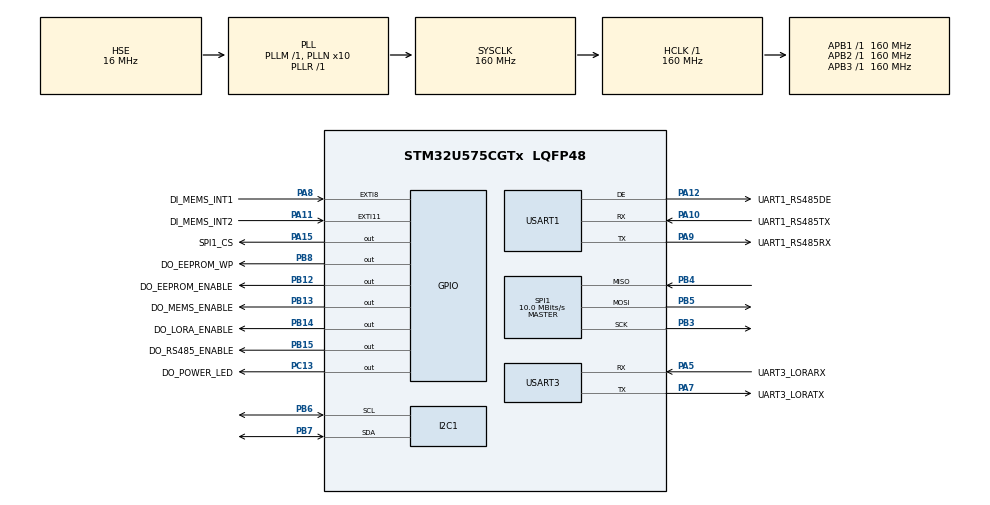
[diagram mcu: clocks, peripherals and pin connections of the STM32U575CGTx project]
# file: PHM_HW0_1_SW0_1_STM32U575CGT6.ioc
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CORTEX_M33_NS.userName=CORTEX_M33
GPDMA1.CIRCULARMODE_GPDMACH0=ENABLE
GPDMA1.CIRCULARMODE_GPDMACH1=DISABLE
GPDMA1.CIRCULARMODE_GPDMACH2=ENABLE
GPDMA1.DESTINC_GPDMACH0=DMA_DINC_INCREMENTED
GPDMA1.DESTINC_GPDMACH1=DMA_DINC_FIXED
GPDMA1.DESTINC_GPDMACH2=DMA_DINC_INCREMENTED
GPDMA1.IPHANDLE_GPDMACH0-SIMPLEREQUEST_GPDMACH0=__NULL
GPDMA1.IPHANDLE_GPDMACH1-SIMPLEREQUEST_GPDMACH1=__NULL
GPDMA1.IPHANDLE_GPDMACH2-SIMPLEREQUEST_GPDMACH2=__NULL
GPDMA1.IPHANDLE_GPDMACH3-SIMPLEREQUEST_GPDMACH3=__NULL
GPDMA1.IPHANDLE_GPDMACH4-SIMPLEREQUEST_GPDMACH4=__NULL
GPDMA1.IPHANDLE_GPDMACH5-SIMPLEREQUEST_GPDMACH5=__NULL
GPDMA1.LINKALLOCATEDPORT_CIRCULAR_GPDMACH1=DMA_LINK_ALLOCATED_PORT1
GPDMA1.REQUEST_GPDMACH0=GPDMA1_REQUEST_USART1_RX
GPDMA1.REQUEST_GPDMACH1=GPDMA1_REQUEST_USART1_TX
GPDMA1.REQUEST_GPDMACH2=GPDMA1_REQUEST_USART3_RX
GPDMA1.REQUEST_GPDMACH3=GPDMA1_REQUEST_USART3_TX
GPDMA1.REQUEST_GPDMACH4=GPDMA1_REQUEST_SPI1_TX
GPDMA1.REQUEST_GPDMACH5=GPDMA1_REQUEST_SPI1_RX
GPDMA1.SRCINC_GPDMACH1=DMA_SINC_INCREMENTED
GPDMA1.SRCINC_GPDMACH3=DMA_SINC_INCREMENTED
I2C1.Timing=0x30909DEC
Mcu.Family=STM32U5
Mcu.Name=STM32U575CGTx
Mcu.Package=LQFP48
NVIC.GPDMA1_Channel0_IRQn=true\:0\:0\:false\:false\:true\:true\:true\:true
NVIC.GPDMA1_Channel1_IRQn=true\:0\:0\:false\:false\:true\:true\:true\:true
NVIC.GPDMA1_Channel2_IRQn=true\:0\:0\:false\:false\:true\:false\:true\:true
NVIC.GPDMA1_Channel3_IRQn=true\:0\:0\:false\:false\:true\:false\:true\:true
NVIC.GPDMA1_Channel4_IRQn=true\:0\:0\:false\:false\:true\:false\:true\:true
NVIC.GPDMA1_Channel5_IRQn=true\:0\:0\:false\:false\:true\:false\:true\:true
NVIC.PriorityGroup=NVIC_PRIORITYGROUP_4
NVIC.SPI1_IRQn=true\:0\:0\:false\:false\:true\:true\:true\:true
NVIC.USART1_IRQn=true\:0\:0\:false\:false\:true\:true\:true\:true
NVIC.USART3_IRQn=true\:0\:0\:false\:false\:true\:true\:true\:true
PA10.GPIO_Label=UART1_RS485TX
PA10.Mode=Asynchronous
PA10.Signal=USART1_RX
PA11.GPIO_Label=DI_MEMS_INT2
PA11.GPIO_ModeDefaultEXTI=GPIO_MODE_IT_RISING
PA11.Signal=GPXTI11
PA12.GPIO_Label=UART1_RS485DE
PA12.Mode=Hardware Flow Control (RS485)
PA12.Signal=USART1_DE
PA13\ (JTMS/SWDIO).Mode=Serial_Wire
PA13\ (JTMS/SWDIO).Signal=DEBUG_JTMS-SWDIO
PA14\ (JTCK/SWCLK).Mode=Serial_Wire
PA14\ (JTCK/SWCLK).Signal=DEBUG_JTCK-SWCLK
PA15\ (JTDI).GPIO_Label=SPI1_CS
PA15\ (JTDI).Signal=GPIO_Output
PA5.GPIO_Label=UART3_LORARX
PA5.Mode=Asynchronous
PA5.Signal=USART3_RX
PA7.GPIO_Label=UART3_LORATX
PA7.Mode=Asynchronous
PA7.Signal=USART3_TX
PA8.GPIO_Label=DI_MEMS_INT1
PA8.GPIO_ModeDefaultEXTI=GPIO_MODE_IT_RISING
PA8.Signal=GPXTI8
PA9.GPIO_Label=UART1_RS485RX
PA9.Mode=Asynchronous
PA9.Signal=USART1_TX
PB12.GPIO_Label=DO_EEPROM_ENABLE
PB12.GPIO_ModeDefaultOutputPP=GPIO_MODE_OUTPUT_OD
PB12.GPIO_PuPd=GPIO_NOPULL
PB12.PinState=GPIO_PIN_SET
PB12.Signal=GPIO_Output
PB13.GPIO_Label=DO_MEMS_ENABLE
PB13.GPIO_ModeDefaultOutputPP=GPIO_MODE_OUTPUT_OD
PB13.GPIO_PuPd=GPIO_NOPULL
PB13.PinState=GPIO_PIN_SET
PB13.Signal=GPIO_Output
PB14.GPIO_Label=DO_LORA_ENABLE
PB14.GPIO_ModeDefaultOutputPP=GPIO_MODE_OUTPUT_OD
PB14.GPIO_PuPd=GPIO_NOPULL
PB14.PinState=GPIO_PIN_SET
PB14.Signal=GPIO_Output
PB15.GPIO_Label=DO_RS485_ENABLE
PB15.GPIO_ModeDefaultOutputPP=GPIO_MODE_OUTPUT_OD
PB15.GPIO_PuPd=GPIO_NOPULL
PB15.PinState=GPIO_PIN_SET
PB15.Signal=GPIO_Output
PB3\ (JTDO/TRACESWO).GPIO_PuPd=GPIO_NOPULL
PB3\ (JTDO/TRACESWO).GPIO_Speed=GPIO_SPEED_FREQ_HIGH
PB3\ (JTDO/TRACESWO).Mode=Full_Duplex_Master
PB3\ (JTDO/TRACESWO).Signal=SPI1_SCK
PB4\ (NJTRST).GPIO_PuPd=GPIO_NOPULL
PB4\ (NJTRST).GPIO_Speed=GPIO_SPEED_FREQ_HIGH
PB4\ (NJTRST).Mode=Full_Duplex_Master
PB4\ (NJTRST).Signal=SPI1_MISO
PB5.GPIO_PuPd=GPIO_NOPULL
PB5.GPIO_Speed=GPIO_SPEED_FREQ_HIGH
PB5.Mode=Full_Duplex_Master
PB5.Signal=SPI1_MOSI
PB6.Mode=I2C
PB6.Signal=I2C1_SCL
PB7.Mode=I2C
PB7.Signal=I2C1_SDA
PB8.GPIO_Label=DO_EEPROM_WP
PB8.Signal=GPIO_Output
PC13.GPIO_Label=DO_POWER_LED
PC13.GPIO_ModeDefaultOutputPP=GPIO_MODE_OUTPUT_OD
PC13.GPIO_PuPd=GPIO_NOPULL
PC13.PinState=GPIO_PIN_SET
PC13.Signal=GPIO_Output
PH0-OSC_IN\ (PH0).Mode=HSE-External-Oscillator
PH0-OSC_IN\ (PH0).Signal=RCC_OSC_IN
PH1-OSC_OUT\ (PH1).Mode=HSE-External-Oscillator
PH1-OSC_OUT\ (PH1).Signal=RCC_OSC_OUT
ProjectManager.HeapSize=0x200
ProjectManager.StackSize=0x400
ProjectManager.TargetToolchain=STM32CubeIDE
RCC.ADCFreq_Value=16000000
RCC.AHBFreq_Value=160000000
RCC.APB1Freq_Value=160000000
RCC.APB1TimFreq_Value=160000000
RCC.APB2Freq_Value=160000000
RCC.APB2TimFreq_Value=160000000
RCC.APB3Freq_Value=160000000
RCC.CortexFreq_Value=160000000
RCC.EPOD_VALUE=16000000
RCC.HCLKFreq_Value=160000000
RCC.HSE_VALUE=16000000
RCC.HSI48_VALUE=48000000
RCC.HSI_VALUE=16000000
RCC.LSE_VALUE=32768
RCC.LSIDIV_VALUE=32000
RCC.MSI_VALUE=4000000
RCC.PLL1R=1
RCC.PLLFRACN=0
RCC.PLLN=10
RCC.PLLSourceVirtual=RCC_PLLSOURCE_HSE
RCC.SYSCLKFreq_VALUE=160000000
RCC.SYSCLKSource=RCC_SYSCLKSOURCE_PLLCLK
RCC.USBFreq_Value=48000000
RCC.VCOOutputFreq_Value=160000000
SPI1.BaudRatePrescaler=SPI_BAUDRATEPRESCALER_16
SPI1.CalculateBaudRate=10.0 MBits/s
SPI1.DataSize=SPI_DATASIZE_8BIT
SPI1.Direction=SPI_DIRECTION_2LINES
SPI1.IOSwap=SPI_IO_SWAP_ENABLE
SPI1.Mode=SPI_MODE_MASTER
SPI1.VirtualType=VM_MASTER
USART1.VirtualMode-Asynchronous=VM_ASYNC
USART1.VirtualMode-Hardware\ Flow\ Control\ (RS485)=VM_ASYNC
USART3.VirtualMode-Asynchronous=VM_ASYNC
VP_GPDMA1_VS_GPDMACH0.Mode=SIMPLEREQUEST_GPDMACH0
VP_GPDMA1_VS_GPDMACH1.Mode=SIMPLEREQUEST_GPDMACH1
VP_GPDMA1_VS_GPDMACH2.Mode=SIMPLEREQUEST_GPDMACH2
VP_GPDMA1_VS_GPDMACH3.Mode=SIMPLEREQUEST_GPDMACH3
VP_GPDMA1_VS_GPDMACH4.Mode=SIMPLEREQUEST_GPDMACH4
VP_GPDMA1_VS_GPDMACH5.Mode=SIMPLEREQUEST_GPDMACH5
VP_ICACHE_VS_ENABLE_ICACHE_MEMORY.Mode=Memoryregions
VP_ICACHE_VS_ICACHE.Mode=DefaultMode
VP_LPBAMQUEUE_VS_QUEUE.Mode=QUEUEMODE
VP_LPBAM_VS_SIG1.Mode=SmartRun
VP_LPBAM_VS_SIG4.Mode=LPDMA1
VP_MEMORYMAP_VS_MEMORYMAP.Mode=CurAppReg
VP_PWR_VS_SECSignals.Mode=Security/Privilege
board=custom

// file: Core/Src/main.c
/* USER CODE BEGIN Header */
/**
  ******************************************************************************
  * @file           : main.c
  * @brief          : Main program body
  ******************************************************************************
  * @attention
  *
  * Copyright (c) 2026 STMicroelectronics.
  * All rights reserved.
  *
  * This software is licensed under terms that can be found in the LICENSE file
  * in the root directory of this software component.
  * If no LICENSE file comes with this software, it is provided AS-IS.
  *
  ******************************************************************************
  */
/* USER CODE END Header */
#include "main.h"

/* USER CODE BEGIN Includes */
#include "Mi_Main.h"
/* USER CODE END Includes */

I2C_HandleTypeDef hi2c1;

SPI_HandleTypeDef hspi1;
DMA_HandleTypeDef handle_GPDMA1_Channel5;
DMA_HandleTypeDef handle_GPDMA1_Channel4;

UART_HandleTypeDef huart1;
UART_HandleTypeDef huart3;
DMA_HandleTypeDef handle_GPDMA1_Channel1;
DMA_NodeTypeDef Node_GPDMA1_Channel0;
DMA_QListTypeDef List_GPDMA1_Channel0;
DMA_HandleTypeDef handle_GPDMA1_Channel0;
DMA_HandleTypeDef handle_GPDMA1_Channel3;
DMA_NodeTypeDef Node_GPDMA1_Channel2;
DMA_QListTypeDef List_GPDMA1_Channel2;
DMA_HandleTypeDef handle_GPDMA1_Channel2;

void SystemClock_Config(void);
static void MX_GPIO_Init(void);
static void MX_GPDMA1_Init(void);
static void MX_I2C1_Init(void);
static void MX_SPI1_Init(void);
static void MX_USART1_UART_Init(void);
static void MX_USART3_UART_Init(void);
static void MX_ICACHE_Init(void);

int main(void)
{

  /* MCU Configuration--------------------------------------------------------*/

  /* Reset of all peripherals, Initializes the Flash interface and the Systick. */
  HAL_Init();

  /* Configure the system clock */
  SystemClock_Config();

  /* Initialize all configured peripherals */
  MX_GPIO_Init();
  MX_GPDMA1_Init();
  MX_I2C1_Init();
  MX_SPI1_Init();
  MX_USART1_UART_Init();
  MX_USART3_UART_Init();
  MX_ICACHE_Init();

  /* Infinite loop */
  while (1)
  {

    /* USER CODE BEGIN 3 */
	  MiMain();
  }
  /* USER CODE END 3 */
}

void SystemClock_Config(void)
{
  RCC_OscInitTypeDef RCC_OscInitStruct = {0};
  RCC_ClkInitTypeDef RCC_ClkInitStruct = {0};

  /** Configure the main internal regulator output voltage
  */
  if (HAL_PWREx_ControlVoltageScaling(PWR_REGULATOR_VOLTAGE_SCALE1) != HAL_OK)
  {
    Error_Handler();
  }

  /** Initializes the CPU, AHB and APB buses clocks
  */
  RCC_OscInitStruct.OscillatorType = RCC_OSCILLATORTYPE_HSE;
  RCC_OscInitStruct.HSEState = RCC_HSE_ON;
  RCC_OscInitStruct.PLL.PLLState = RCC_PLL_ON;
  RCC_OscInitStruct.PLL.PLLSource = RCC_PLLSOURCE_HSE;
  RCC_OscInitStruct.PLL.PLLMBOOST = RCC_PLLMBOOST_DIV1;
  RCC_OscInitStruct.PLL.PLLM = 1;
  RCC_OscInitStruct.PLL.PLLN = 10;
  RCC_OscInitStruct.PLL.PLLP = 2;
  RCC_OscInitStruct.PLL.PLLQ = 2;
  RCC_OscInitStruct.PLL.PLLR = 1;
  RCC_OscInitStruct.PLL.PLLRGE = RCC_PLLVCIRANGE_1;
  RCC_OscInitStruct.PLL.PLLFRACN = 0;
  if (HAL_RCC_OscConfig(&RCC_OscInitStruct) != HAL_OK)
  {
    Error_Handler();
  }

  /** Initializes the CPU, AHB and APB buses clocks
  */
  RCC_ClkInitStruct.ClockType = RCC_CLOCKTYPE_HCLK|RCC_CLOCKTYPE_SYSCLK
                              |RCC_CLOCKTYPE_PCLK1|RCC_CLOCKTYPE_PCLK2
                              |RCC_CLOCKTYPE_PCLK3;
  RCC_ClkInitStruct.SYSCLKSource = RCC_SYSCLKSOURCE_PLLCLK;
  RCC_ClkInitStruct.AHBCLKDivider = RCC_SYSCLK_DIV1;
  RCC_ClkInitStruct.APB1CLKDivider = RCC_HCLK_DIV1;
  RCC_ClkInitStruct.APB2CLKDivider = RCC_HCLK_DIV1;
  RCC_ClkInitStruct.APB3CLKDivider = RCC_HCLK_DIV1;

  if (HAL_RCC_ClockConfig(&RCC_ClkInitStruct, FLASH_LATENCY_4) != HAL_OK)
  {
    Error_Handler();
  }
}

static void MX_GPDMA1_Init(void)
{

  /* Peripheral clock enable */
  __HAL_RCC_GPDMA1_CLK_ENABLE();

  /* GPDMA1 interrupt Init */
    HAL_NVIC_SetPriority(GPDMA1_Channel0_IRQn, 0, 0);
    HAL_NVIC_EnableIRQ(GPDMA1_Channel0_IRQn);
    HAL_NVIC_SetPriority(GPDMA1_Channel1_IRQn, 0, 0);
    HAL_NVIC_EnableIRQ(GPDMA1_Channel1_IRQn);
    HAL_NVIC_SetPriority(GPDMA1_Channel2_IRQn, 0, 0);
    HAL_NVIC_EnableIRQ(GPDMA1_Channel2_IRQn);
    HAL_NVIC_SetPriority(GPDMA1_Channel3_IRQn, 0, 0);
    HAL_NVIC_EnableIRQ(GPDMA1_Channel3_IRQn);
    HAL_NVIC_SetPriority(GPDMA1_Channel4_IRQn, 0, 0);
    HAL_NVIC_EnableIRQ(GPDMA1_Channel4_IRQn);
    HAL_NVIC_SetPriority(GPDMA1_Channel5_IRQn, 0, 0);
    HAL_NVIC_EnableIRQ(GPDMA1_Channel5_IRQn);

}

static void MX_I2C1_Init(void)
{

  hi2c1.Instance = I2C1;
  hi2c1.Init.Timing = 0x30909DEC;
  hi2c1.Init.OwnAddress1 = 0;
  hi2c1.Init.AddressingMode = I2C_ADDRESSINGMODE_7BIT;
  hi2c1.Init.DualAddressMode = I2C_DUALADDRESS_DISABLE;
  hi2c1.Init.OwnAddress2 = 0;
  hi2c1.Init.OwnAddress2Masks = I2C_OA2_NOMASK;
  hi2c1.Init.GeneralCallMode = I2C_GENERALCALL_DISABLE;
  hi2c1.Init.NoStretchMode = I2C_NOSTRETCH_DISABLE;
  if (HAL_I2C_Init(&hi2c1) != HAL_OK)
  {
    Error_Handler();
  }

  /** Configure Analogue filter
  */
  if (HAL_I2CEx_ConfigAnalogFilter(&hi2c1, I2C_ANALOGFILTER_ENABLE) != HAL_OK)
  {
    Error_Handler();
  }

  /** Configure Digital filter
  */
  if (HAL_I2CEx_ConfigDigitalFilter(&hi2c1, 0) != HAL_OK)
  {
    Error_Handler();
  }

}

static void MX_ICACHE_Init(void)
{

  /** Enable instruction cache (default 2-ways set associative cache)
  */
  if (HAL_ICACHE_Enable() != HAL_OK)
  {
    Error_Handler();
  }

}

static void MX_SPI1_Init(void)
{

  SPI_AutonomousModeConfTypeDef HAL_SPI_AutonomousMode_Cfg_Struct = {0};

  /* SPI1 parameter configuration*/
  hspi1.Instance = SPI1;
  hspi1.Init.Mode = SPI_MODE_MASTER;
  hspi1.Init.Direction = SPI_DIRECTION_2LINES;
  hspi1.Init.DataSize = SPI_DATASIZE_8BIT;
  hspi1.Init.CLKPolarity = SPI_POLARITY_LOW;
  hspi1.Init.CLKPhase = SPI_PHASE_1EDGE;
  hspi1.Init.NSS = SPI_NSS_SOFT;
  hspi1.Init.BaudRatePrescaler = SPI_BAUDRATEPRESCALER_16;
  hspi1.Init.FirstBit = SPI_FIRSTBIT_MSB;
  hspi1.Init.TIMode = SPI_TIMODE_DISABLE;
  hspi1.Init.CRCCalculation = SPI_CRCCALCULATION_DISABLE;
  hspi1.Init.CRCPolynomial = 0x7;
  hspi1.Init.NSSPMode = SPI_NSS_PULSE_ENABLE;
  hspi1.Init.NSSPolarity = SPI_NSS_POLARITY_LOW;
  hspi1.Init.FifoThreshold = SPI_FIFO_THRESHOLD_01DATA;
  hspi1.Init.MasterSSIdleness = SPI_MASTER_SS_IDLENESS_00CYCLE;
  hspi1.Init.MasterInterDataIdleness = SPI_MASTER_INTERDATA_IDLENESS_00CYCLE;
  hspi1.Init.MasterReceiverAutoSusp = SPI_MASTER_RX_AUTOSUSP_DISABLE;
  hspi1.Init.MasterKeepIOState = SPI_MASTER_KEEP_IO_STATE_DISABLE;
  hspi1.Init.IOSwap = SPI_IO_SWAP_ENABLE;
  hspi1.Init.ReadyMasterManagement = SPI_RDY_MASTER_MANAGEMENT_INTERNALLY;
  hspi1.Init.ReadyPolarity = SPI_RDY_POLARITY_HIGH;
  if (HAL_SPI_Init(&hspi1) != HAL_OK)
  {
    Error_Handler();
  }
  HAL_SPI_AutonomousMode_Cfg_Struct.TriggerState = SPI_AUTO_MODE_DISABLE;
  HAL_SPI_AutonomousMode_Cfg_Struct.TriggerSelection = SPI_GRP1_GPDMA_CH0_TCF_TRG;
  HAL_SPI_AutonomousMode_Cfg_Struct.TriggerPolarity = SPI_TRIG_POLARITY_RISING;
  if (HAL_SPIEx_SetConfigAutonomousMode(&hspi1, &HAL_SPI_AutonomousMode_Cfg_Struct) != HAL_OK)
  {
    Error_Handler();
  }

}

static void MX_USART1_UART_Init(void)
{

  huart1.Instance = USART1;
  huart1.Init.BaudRate = 115200;
  huart1.Init.WordLength = UART_WORDLENGTH_8B;
  huart1.Init.StopBits = UART_STOPBITS_1;
  huart1.Init.Parity = UART_PARITY_NONE;
  huart1.Init.Mode = UART_MODE_TX_RX;
  huart1.Init.HwFlowCtl = UART_HWCONTROL_NONE;
  huart1.Init.OverSampling = UART_OVERSAMPLING_16;
  huart1.Init.OneBitSampling = UART_ONE_BIT_SAMPLE_DISABLE;
  huart1.Init.ClockPrescaler = UART_PRESCALER_DIV1;
  huart1.AdvancedInit.AdvFeatureInit = UART_ADVFEATURE_NO_INIT;
  if (HAL_RS485Ex_Init(&huart1, UART_DE_POLARITY_HIGH, 0, 0) != HAL_OK)
  {
    Error_Handler();
  }
  if (HAL_UARTEx_SetTxFifoThreshold(&huart1, UART_TXFIFO_THRESHOLD_1_8) != HAL_OK)
  {
    Error_Handler();
  }
  if (HAL_UARTEx_SetRxFifoThreshold(&huart1, UART_RXFIFO_THRESHOLD_1_8) != HAL_OK)
  {
    Error_Handler();
  }
  if (HAL_UARTEx_DisableFifoMode(&huart1) != HAL_OK)
  {
    Error_Handler();
  }

}

static void MX_USART3_UART_Init(void)
{

  huart3.Instance = USART3;
  huart3.Init.BaudRate = 115200;
  huart3.Init.WordLength = UART_WORDLENGTH_8B;
  huart3.Init.StopBits = UART_STOPBITS_1;
  huart3.Init.Parity = UART_PARITY_NONE;
  huart3.Init.Mode = UART_MODE_TX_RX;
  huart3.Init.HwFlowCtl = UART_HWCONTROL_NONE;
  huart3.Init.OverSampling = UART_OVERSAMPLING_16;
  huart3.Init.OneBitSampling = UART_ONE_BIT_SAMPLE_DISABLE;
  huart3.Init.ClockPrescaler = UART_PRESCALER_DIV1;
  huart3.AdvancedInit.AdvFeatureInit = UART_ADVFEATURE_NO_INIT;
  if (HAL_UART_Init(&huart3) != HAL_OK)
  {
    Error_Handler();
  }
  if (HAL_UARTEx_SetTxFifoThreshold(&huart3, UART_TXFIFO_THRESHOLD_1_8) != HAL_OK)
  {
    Error_Handler();
  }
  if (HAL_UARTEx_SetRxFifoThreshold(&huart3, UART_RXFIFO_THRESHOLD_1_8) != HAL_OK)
  {
    Error_Handler();
  }
  if (HAL_UARTEx_DisableFifoMode(&huart3) != HAL_OK)
  {
    Error_Handler();
  }

}

static void MX_GPIO_Init(void)
{
  GPIO_InitTypeDef GPIO_InitStruct = {0};

  /* GPIO Ports Clock Enable */
  __HAL_RCC_GPIOC_CLK_ENABLE();
  __HAL_RCC_GPIOH_CLK_ENABLE();
  __HAL_RCC_GPIOA_CLK_ENABLE();
  __HAL_RCC_GPIOB_CLK_ENABLE();

  /*Configure GPIO pin Output Level */
  HAL_GPIO_WritePin(DO_POWER_LED_GPIO_Port, DO_POWER_LED_Pin, GPIO_PIN_SET);

  /*Configure GPIO pin Output Level */
  HAL_GPIO_WritePin(GPIOB, DO_EEPROM_ENABLE_Pin|DO_MEMS_ENABLE_Pin|DO_LORA_ENABLE_Pin|DO_RS485_ENABLE_Pin, GPIO_PIN_SET);

  /*Configure GPIO pin Output Level */
  HAL_GPIO_WritePin(SPI1_CS_GPIO_Port, SPI1_CS_Pin, GPIO_PIN_RESET);

  /*Configure GPIO pin Output Level */
  HAL_GPIO_WritePin(DO_EEPROM_WP_GPIO_Port, DO_EEPROM_WP_Pin, GPIO_PIN_RESET);

  /*Configure GPIO pin : DO_POWER_LED_Pin */
  GPIO_InitStruct.Pin = DO_POWER_LED_Pin;
  GPIO_InitStruct.Mode = GPIO_MODE_OUTPUT_OD;
  GPIO_InitStruct.Pull = GPIO_NOPULL;
  GPIO_InitStruct.Speed = GPIO_SPEED_FREQ_LOW;
  HAL_GPIO_Init(DO_POWER_LED_GPIO_Port, &GPIO_InitStruct);

  /*Configure GPIO pins : DO_EEPROM_ENABLE_Pin DO_MEMS_ENABLE_Pin DO_LORA_ENABLE_Pin DO_RS485_ENABLE_Pin */
  GPIO_InitStruct.Pin = DO_EEPROM_ENABLE_Pin|DO_MEMS_ENABLE_Pin|DO_LORA_ENABLE_Pin|DO_RS485_ENABLE_Pin;
  GPIO_InitStruct.Mode = GPIO_MODE_OUTPUT_OD;
  GPIO_InitStruct.Pull = GPIO_NOPULL;
  GPIO_InitStruct.Speed = GPIO_SPEED_FREQ_LOW;
  HAL_GPIO_Init(GPIOB, &GPIO_InitStruct);

  /*Configure GPIO pins : DI_MEMS_INT1_Pin DI_MEMS_INT2_Pin */
  GPIO_InitStruct.Pin = DI_MEMS_INT1_Pin|DI_MEMS_INT2_Pin;
  GPIO_InitStruct.Mode = GPIO_MODE_IT_RISING;
  GPIO_InitStruct.Pull = GPIO_NOPULL;
  HAL_GPIO_Init(GPIOA, &GPIO_InitStruct);

  /*Configure GPIO pin : SPI1_CS_Pin */
  GPIO_InitStruct.Pin = SPI1_CS_Pin;
  GPIO_InitStruct.Mode = GPIO_MODE_OUTPUT_PP;
  GPIO_InitStruct.Pull = GPIO_NOPULL;
  GPIO_InitStruct.Speed = GPIO_SPEED_FREQ_LOW;
  HAL_GPIO_Init(SPI1_CS_GPIO_Port, &GPIO_InitStruct);

  /*Configure GPIO pin : DO_EEPROM_WP_Pin */
  GPIO_InitStruct.Pin = DO_EEPROM_WP_Pin;
  GPIO_InitStruct.Mode = GPIO_MODE_OUTPUT_PP;
  GPIO_InitStruct.Pull = GPIO_NOPULL;
  GPIO_InitStruct.Speed = GPIO_SPEED_FREQ_LOW;
  HAL_GPIO_Init(DO_EEPROM_WP_GPIO_Port, &GPIO_InitStruct);

}

void Error_Handler(void)
{
  __disable_irq();
  while (1)
  {
  }
}
